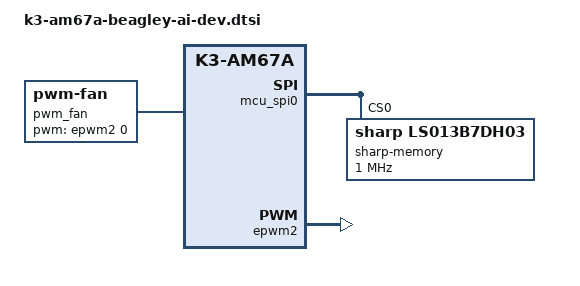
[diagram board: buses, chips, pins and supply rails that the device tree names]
/ {
	pwm_fan: pwm-fan {
		compatible = "pwm-fan";
		status = "okay";
		pwms = <&epwm2 0 40000 20000>;
		cooling-levels = <0 64 128 255>;
		#cooling-cells = <2>;
	};
};

&mcu_pmx0 {
	mcu_spi0_pins_default: mcu-spi0-default-pins {
		pinctrl-single,pins = <
			J722S_IOPAD(0x0008, PIN_INPUT, 0) /* (A9)  MCU_SPI0_CLK */
			J722S_IOPAD(0x000c, PIN_INPUT, 0) /* (B12) MCU_SPI0_MOSI */
			J722S_IOPAD(0x0010, PIN_INPUT, 0) /* (C11) MCU_SPI0_MISO */
			J722S_IOPAD(0x0000, PIN_INPUT, 0) /* (C12) MCU_SPI0_CS0 */
		>;
		bootph-all;
	};

	mcu_i2c0_pins_default: mcu-i2c0-default-pins {
		pinctrl-single,pins = <
			J722S_IOPAD(0x0044, PIN_INPUT_PULLUP, 0) /* (B13) I2C0_SCL */
			J722S_IOPAD(0x0048, PIN_INPUT_PULLUP, 0) /* (E11) I2C0_SDA*/
		>;
		bootph-all;
	};
};

&main_pmx0 {
	main_epwm2_pin_default: main-epwm2-default-pin {
		pinctrl-single,pins = <
			J722S_IOPAD(0x0124, PIN_INPUT, 4) /* (F26) EHRPWM2_A */
		>;
	};

	main_mcasp0_pins_default: main-mcasp0-default-pins {
		pinctrl-single,pins = <
			J722S_IOPAD(0x01a4, PIN_INPUT, 0) /* (D25) McASP0_ACLKX */
			J722S_IOPAD(0x01a8, PIN_INPUT, 0) /* (C26) McASP0_AFSX */
			J722S_IOPAD(0x01a0, PIN_OUTPUT, 0) /* (F23) McASP0_AXR0 */
		>;
	};

};

&mcu_spi0 {
	status = "okay";
	pinctrl-names = "default";
	pinctrl-0 = <&mcu_spi0_pins_default>;
	sharp-memory@0 {
		compatible = "sharp,ls013b7dh03";
		reg = <0>;
		spi-cs-high;
		spi-max-frequency = <1000000>;
		sharp,vcom-mode = "software";
	};
};

&epwm2 {
	status = "okay";
	pinctrl-names = "default";
	pinctrl-0 = <&main_epwm2_pin_default>;
};
